# NUC123BN_v1 register map
File version: 1.0
Registers are 32-bit, read-write, reset 0x0 unless marked. A register's access mark holds for its fields unless they carry their own. Offsets are from the block's base; [hi:lo] are bit positions.

## CRC — PDMA Register Map
Base 0x50008E00
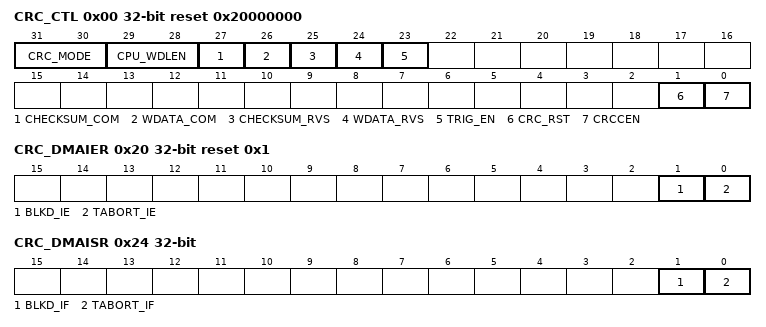
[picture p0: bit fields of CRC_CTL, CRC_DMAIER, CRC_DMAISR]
0x00 CRC_CTL reset 0x20000000 — CRC Control Register
  [31:30] CRC_MODE — CRC Polynomial Mode
    0=CRC-CCITT Polynomial mode; 1=CRC-8 Polynomial mode; 2=CRC-16 Polynomial mode; 3=CRC-32 Polynomial mode
  [29:28] CPU_WDLEN — CPU Write Data Length. Note1: This field is used for CPU PIO mode. Note2: When the data length is 8-bit mode, the valid data is CRC_WDATA [7:0]; if the data length is 16-bit mode, the valid data is CRC_WDATA [15:0].
    0=Data length is 8-bit mode; 1=Data length is 16-bit mode. Data length is 32-bit mode
  [27] CHECKSUM_COM — Checksum Complement
    0=No 1's complement for CRC checksum; 1=1's complement for CRC checksum
  [26] WDATA_COM — Write Data Complement
    0=No 1's complement for CRC write data in; 1=1's complement for CRC write data in
  [25] CHECKSUM_RVS — Checksum Reverse. Note: If the checksum data is 0XDD7B0F2E, the bit order reversed for CRC checksum is 0x74F0DEBB.
    0=No bit order reverse for CRC checksum; 1=Bit order reverse for CRC checksum
  [24] WDATA_RVS — Write Data Order Reverse. Note: If the write data is 0xAABBCCDD, the bit order reverse for CRC write data in is 0x55DD33BB
    0=No bit order reversed for CRC write data in; 1=Bit order reversed for CRC write data in (per byte)
  [23] TRIG_EN — TRIG_EN. Note1: If this bit assert indicates the CRC engine operation in CRC DMA mode, do not fill in any data in CRC_WDATA register. Note2: When CRC DMA transfer is completed, this bit will be cleared automatically. Note3: If the bus error occurs, all CRC DMA transfer will be stopped. Software must reset all DMA channel, and then trigger again.
    0=No effect; 1=CRC DMA data read or write transfer Enabled
  [1] CRC_RST — CRC Engine Reset. Note: When operated in CPU PIO mode, setting this bit will reload the initial seed value.
    0=No effect; 1=Reset the internal CRC state machine and internal buffer. The contents of control register will not be cleared. This bit will automatically be cleared after few clock cycles
  [0] CRCCEN — CRC Channel Enable. Setting this bit to 1 enables CRC's operation.
0x04 CRC_DMASAR — CRC DMA Transfer Source Address Register
  [31:0] CRC_DMASAR — CRC DMA Transfer Source Address Register. This field indicates a 32-bit source address of CRC DMA. Note: The source address must be word alignment.
0x0C CRC_DMABCR — CRC DMA Transfer Byte Count Register
  [15:0] CRC_DMABCR — CRC DMA Transfer Byte Count Register. This field indicates a 16-bit transfer byte count number of CRC DMA.
0x14 CRC_DMACSAR ro — CRC DMA Current Source Address Register
  [31:0] CRC_DMACSAR — CRC DMA Current Source Address Register (Read Only). This field indicates the source address where the CRC DMA transfer just occurs.
0x1C CRC_DMACBCR ro — CRC DMA Current Byte Count Register
  [15:0] CRC_DMACBCR — CRC DMA Current Byte Count Register (Read Only). This field indicates the current remained byte count of CRC_DMA. Note: CRC_RST will clear this register value.
0x20 CRC_DMAIER reset 0x1 — CRC DMA Interrupt Enable Control Register
  [1] BLKD_IE — CRC DMA Transfer Done Interrupt Enable
    0=Interrupt generator Disabled when CRC DMA transfer is done; 1=Interrupt generator Enabled when CRC DMA transfer is done
  [0] TABORT_IE — CRC DMA Read/Write Target Abort Interrupt Enable
    0=Target abort interrupt generation Disabled during CRC DMA transfer; 1=Target abort interrupt generation Enabled during CRC DMA transfer
0x24 CRC_DMAISR — CRC DMA Interrupt Status Register
  [1] BLKD_IF — Block Transfer Done Interrupt Flag. This bit indicates that CRC DMA has finished all transfer. Software can write 1 to clear this bit to zero.
    0=Not finished; 1=Done
  [0] TABORT_IF — CRC DMA Read/Write Target Abort Interrupt Flag. Software can write 1 to clear this bit to zero.
    0=No bus ERROR response received; 1=Bus ERROR response received
0x80 CRC_WDATA — CRC Write Data Register
0x84 CRC_SEED reset 0xFFFFFFFF
  [31:0] CRC_SEED — CRC Seed Register. This field indicates the CRC seed value.
0x88 CRC_CHECKSUM ro
  [31:0] CRC_CHECKSUM — CRC Checksum Register. This field indicates the CRC checksum.
